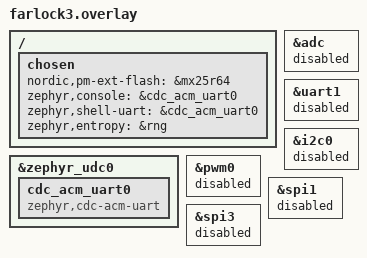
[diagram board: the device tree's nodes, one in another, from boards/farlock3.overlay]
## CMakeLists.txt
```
cmake_minimum_required(VERSION 3.20.0)

find_package(Zephyr HINTS $ENV{ZEPHYR_BASE})

project(app)

# Enable GNU STD support.
include(${ZEPHYR_CONNECTEDHOMEIP_MODULE_DIR}/config/nrfconnect/app/enable-gnu-std.cmake)

# NORDIC SDK APP START

# Include all source files that are located in the Matter common directory.
include(${ZEPHYR_NRF_MODULE_DIR}/samples/matter/common/cmake/source_common.cmake)

# Include Data Model utils
include(${ZEPHYR_NRF_MODULE_DIR}/samples/matter/common/cmake/data_model.cmake)

include(${ZEPHYR_NRF_MODULE_DIR}/samples/matter/common/cmake/zap_helpers.cmake)
ncs_get_zap_parent_dir(ZAP_PARENT_DIR)

target_include_directories(app PRIVATE
        src
        ${ZAP_PARENT_DIR}
)

target_sources(app PRIVATE
        #src/app_task.cpp
        #src/main.cpp
        src/main.c
        src/nfc.c
        src/usb.c
)

ncs_configure_data_model()
# NORDIC SDK APP END
```

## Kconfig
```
mainmenu "FARLock3 Application"

# Sample configuration used for Thread networking
if OPENTHREAD

choice OPENTHREAD_NORDIC_LIBRARY_CONFIGURATION
	default OPENTHREAD_NORDIC_LIBRARY_MTD
endchoice

choice OPENTHREAD_DEVICE_TYPE
	default OPENTHREAD_MTD
endchoice

endif # OPENTHREAD

source "${ZEPHYR_CONNECTEDHOMEIP_MODULE_DIR}/config/nrfconnect/chip-module/Kconfig.features"
source "${ZEPHYR_CONNECTEDHOMEIP_MODULE_DIR}/config/nrfconnect/chip-module/Kconfig.defaults"
source "${ZEPHYR_NRF_MODULE_DIR}/samples/matter/common/src/Kconfig"
source "Kconfig.zephyr"
```

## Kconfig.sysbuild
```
#
# Copyright (c) 2023 Nordic Semiconductor ASA
#
# SPDX-License-Identifier: LicenseRef-Nordic-5-Clause
#

config WIFI_NRF70
	default y if BOARD_NRF7002DK

#### Radio core selection
config NRF_DEFAULT_IPC_RADIO
	default y

# Enable IEEE802.15.4 serialization to network core
# This config automatically pulls in the `overlay-802154.conf` in the ipc_radio image
config NETCORE_IPC_RADIO_IEEE802154
	default y if SOC_SERIES_NRF53X && !WIFI_NRF70

# Enable Bluetooth serialization to network core
# This config automatically pulls in the `overlay-bt_hci_ipc.conf` in the ipc_radio image
config NETCORE_IPC_RADIO_BT_HCI_IPC
	default y if SOC_SERIES_NRF53X

#### Bootloader
choice BOOTLOADER
	default BOOTLOADER_MCUBOOT if !BOARD_NRF21540DK
endchoice

if BOOTLOADER_MCUBOOT

#### DFU multi-image support
config DFU_MULTI_IMAGE_PACKAGE_BUILD
	default y

config DFU_MULTI_IMAGE_PACKAGE_APP
	default y

config PM_EXTERNAL_FLASH_MCUBOOT_SECONDARY
	default y

#### DFU network core configuration
if SOC_SERIES_NRF53X

config MCUBOOT_UPDATEABLE_IMAGES
	default 2

choice MCUBOOT_MODE
	default MCUBOOT_MODE_OVERWRITE_ONLY
endchoice

choice BOOT_SIGNATURE_TYPE
	default BOOT_SIGNATURE_TYPE_RSA
endchoice

config SECURE_BOOT_NETCORE
	default y

config NETCORE_APP_UPDATE
	default y

config DFU_MULTI_IMAGE_PACKAGE_NET
	default y

endif # SOC_SERIES_NRF53X

if (BOARD_NRF54L15DK || BOARD_NRF54LM20PDK)

config PM_OVERRIDE_EXTERNAL_DRIVER_CHECK
	default y

endif # (BOARD_NRF54L15DK || BOARD_NRF54LM20PDK)

# Mcuboot padding size is modified to 0x1000 in pm_static file.
if SOC_NRF54L10

config PM_MCUBOOT_PAD
	default 0x1000

endif # SOC_NRF54L10

endif # BOOTLOADER_MCUBOOT

#### Enable generating factory data
config MATTER_FACTORY_DATA_GENERATE
	default y if !BOARD_NRF21540DK

source "share/sysbuild/Kconfig"
```

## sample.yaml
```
# This file is provided so that the application can be compiled using Twister,
# the Zephyr testing tool. In this file, multiple combinations can be specified,
# so that you can easily test all of them locally or in CI.
sample:
  description: NCS FAR Device
  name: example-application
common:
  build_only: true
  integration_platforms:
    - farlock
tests:
  app.default: {}
  app.debug:
    extra_overlay_confs:
      - debug.conf
```

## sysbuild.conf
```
SB_CONFIG_MATTER=y
```

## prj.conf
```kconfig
CONFIG_NCS_APPLICATION_BOOT_BANNER_STRING="FARLock3"

#Enable USB
CONFIG_USB_DEVICE_STACK=y
CONFIG_USB_DEVICE_PRODUCT="FARLock3"
CONFIG_USB_DEVICE_PID=0x0004
CONFIG_USB_DEVICE_INITIALIZE_AT_BOOT=n

#Configure NFC
CONFIG_NFC_T2T_NRFXLIB=y
CONFIG_NFC_NDEF=y
CONFIG_NFC_NDEF_MSG=y
CONFIG_NFC_NDEF_RECORD=y
CONFIG_NFC_NDEF_URI_REC=y
CONFIG_NFC_NDEF_LAUNCHAPP_MSG=y

#Enable Console
CONFIG_SERIAL=y
CONFIG_CONSOLE=y
CONFIG_UART_CONSOLE=y
CONFIG_UART_LINE_CTRL=y

# Enable CHIP
CONFIG_CHIP=y
CONFIG_CHIP_PROJECT_CONFIG="src/chip_project_config.h"

# Configure ZAP file name
CONFIG_NCS_SAMPLE_MATTER_ZAP_FILE_PATH="${APPLICATION_CONFIG_DIR}/src/default_zap/farlock3.zap"

# 32768 == 0x8000 (example Product ID added temporaly,
# but it must be changed with proper PID from the list:
# https://github.com/project-chip/connectedhomeip/blob/482e6fd03196a6de45465a90003947ef4b86e0b1/docs/examples/discussion/PID_allocation_for_example_apps.md)
CONFIG_CHIP_DEVICE_PRODUCT_ID=32768
CONFIG_STD_CPP17=y

# Enable Matter pairing automatically on application start.
CONFIG_CHIP_ENABLE_PAIRING_AUTOSTART=y

# Enable Matter extended announcement and increase duration to 1 hour.
CONFIG_CHIP_BLE_EXT_ADVERTISING=y
CONFIG_CHIP_BLE_ADVERTISING_DURATION=60

# Bluetooth Low Energy configuration
CONFIG_BT_DEVICE_NAME="FARLock3"

# Other settings
CONFIG_THREAD_NAME=y
CONFIG_MPU_STACK_GUARD=y
CONFIG_RESET_ON_FATAL_ERROR=n
CONFIG_CHIP_LIB_SHELL=y
CONFIG_NCS_SAMPLE_MATTER_TEST_SHELL=y

# Disable NFC commissioning
CONFIG_CHIP_NFC_COMMISSIONING=n

# Reduce application size
CONFIG_USE_SEGGER_RTT=n

# Enable Factory Data feature
CONFIG_CHIP_FACTORY_DATA=y
CONFIG_CHIP_FACTORY_DATA_BUILD=y
```

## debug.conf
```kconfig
# Copyright (c) 2021 Nordic Semiconductor ASA
# SPDX-License-Identifier: Apache-2.0
#
# This is a Kconfig fragment which can be used to enable debug-related options
# in the application. See the README for more details.

# compiler
CONFIG_DEBUG_OPTIMIZATIONS=y

# logging
CONFIG_LOG=y
CONFIG_APP_LOG_LEVEL_DBG=y

CONFIG_SHELL=y
CONFIG_PRINTK=y

CONFIG_STDOUT_CONSOLE=y
CONFIG_USB_DEVICE_STACK=y
CONFIG_USB_CDC_ACM=y
CONFIG_USB_DEVICE_MANUFACTURER="frazieje"
CONFIG_USB_DEVICE_PRODUCT="FARLock v2"
CONFIG_USB_DEVICE_PID=0x0001
CONFIG_USB_DRIVER_LOG_LEVEL_ERR=y
CONFIG_UART_INTERRUPT_DRIVEN=y
CONFIG_UART_LINE_CTRL=y
CONFIG_USB_DEVICE_INITIALIZE_AT_BOOT=y
```

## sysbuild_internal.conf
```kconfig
SB_CONFIG_MATTER=y
SB_CONFIG_PM_OVERRIDE_EXTERNAL_DRIVER_CHECK=n
SB_CONFIG_PM_EXTERNAL_FLASH_MCUBOOT_SECONDARY=n

# Enable the DFU image compression.
SB_CONFIG_MCUBOOT_MODE_OVERWRITE_ONLY=y
SB_CONFIG_MCUBOOT_COMPRESSED_IMAGE_SUPPORT=y
```

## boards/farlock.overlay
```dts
/ {
	chosen {
		nordic,pm-ext-flash = &mx25r64;
	};
};

/ {
	chosen {
		zephyr,entropy = &rng;
	};
};

/* Disable unused peripherals to reduce power consumption */
&adc {
	status = "disabled";
};
&uart1 {
	status = "disabled";
};
&i2c0 {
	status = "disabled";
};
&pwm0 {
	status = "disabled";
};
&spi1 {
	status = "disabled";
};
&spi3 {
	status = "disabled";
};
&usbd {
	status = "disabled";
};
```

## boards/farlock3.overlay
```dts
/ {
	chosen {
		nordic,pm-ext-flash = &mx25r64;
	};
};

/ {
	chosen {
		zephyr,console = &cdc_acm_uart0;
	};
};

/ {
	chosen {
		zephyr,shell-uart = &cdc_acm_uart0;
	};
};

/ {
	chosen {
		zephyr,entropy = &rng;
	};
};

&zephyr_udc0 {
	cdc_acm_uart0: cdc_acm_uart0 {
		compatible = "zephyr,cdc-acm-uart";
	};
};

/* Disable unused peripherals to reduce power consumption */
&adc {
	status = "disabled";
};
&uart1 {
	status = "disabled";
};
&i2c0 {
	status = "disabled";
};
&pwm0 {
	status = "disabled";
};
&spi1 {
	status = "disabled";
};
&spi3 {
	status = "disabled";
};
```

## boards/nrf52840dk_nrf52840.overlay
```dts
/* Copyright (c) 2021 Nordic Semiconductor ASA
 *
 * SPDX-License-Identifier: LicenseRef-Nordic-5-Clause
 */

/ {
	chosen {
		nordic,pm-ext-flash = &mx25r64;
	};
};

/ {
	chosen {
		zephyr,console = &cdc_acm_uart0;
	};
};

/ {
	chosen {
		zephyr,shell-uart = &cdc_acm_uart0;
	};
};

/ {
	/*
	* In some default configurations within the nRF Connect SDK,
	* e.g. on nRF52840, the chosen zephyr,entropy node is &cryptocell.
	* This devicetree overlay ensures that default is overridden wherever it
	* is set, as this application uses the RNG node for entropy exclusively.
	*/
	chosen {
		zephyr,entropy = &rng;
	};
};

&zephyr_udc0 {
	cdc_acm_uart0: cdc_acm_uart0 {
		compatible = "zephyr,cdc-acm-uart";
	};
};

/* Disable unused peripherals to reduce power consumption */
&adc {
	status = "disabled";
};
&uart1 {
	status = "disabled";
};
&i2c0 {
	status = "disabled";
};
&pwm0 {
	status = "disabled";
};
&spi1 {
	status = "disabled";
};
&spi3 {
	status = "disabled";
};
```

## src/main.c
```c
#include <zephyr/kernel.h>
#include "nfc.h"
#include "usb.h"

int main()
{
    printk("Started C application \n");

    start_usb();

    start_nfc();

    return 0;
}
```

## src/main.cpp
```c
#include <zephyr/kernel.h>

extern "C" {
#include "nfc.h"
#include "usb.h"
}

#define NFC_PATH DT_PATH(nfc)
#if DT_NODE_EXISTS(NFC_PATH)
#define NFC_TYPE_RO "nfc-ro"
#define NFC_TYPE_RW "nfc-rw"
/**
 * @brief Callback function for handling NFC events.
 */
static void nfc_callback(void *context,
                         nfc_t4t_event_t event,
                         const uint8_t *data,
                         size_t data_length,
                         uint32_t flags)
{
    ARG_UNUSED(context);
    ARG_UNUSED(data);
    ARG_UNUSED(flags);

    switch (event) {
        case NFC_T4T_EVENT_FIELD_ON:
            printk("NFC_T4T_EVENT_FIELD_ON\n");
            break;

        case NFC_T4T_EVENT_FIELD_OFF:
            printk("NFC_T4T_EVENT_FIELD_OFF\n");
            break;

        case NFC_T4T_EVENT_NDEF_READ:
            printk("NFC_T4T_EVENT_NDEF_READ\n");
            break;

        case NFC_T4T_EVENT_NDEF_UPDATED:
            if (data_length > 0) {
                printk("NFC_T4T_EVENT_NDEF_UPDATED\n");
            }
            break;

        default:
            break;
    }
}
#endif

int main()
{
    printk("Started C++ application \n");

    start_usb();


#if DT_NODE_EXISTS(NFC_PATH)
    char nfc_type[] = DT_PROP(NFC_PATH, compatible);
    int result;
    if (strcmp(NFC_TYPE_RO, nfc_type) == 0) {
        printk("NFC type is read only\n");
        result = start_nfc_ro(nfc_callback);
    } else if (strcmp(NFC_TYPE_RW, nfc_type) == 0) {
        printk("NFC type is read write\n");
        result = start_nfc_rw(nfc_callback);
    } else {
        printk("NFC type is unknown, ignoring.\n");
    }
    if (result != 0) {
        printk("Problem starting NFC\n");
        return 0;
    } else {
        printk("NFC tag emulation started!\n");
    }
#endif

    return 0;
}
```

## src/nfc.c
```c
#include "nfc.h"

int start_nfc() {
    return 0;
}
```

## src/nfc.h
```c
#ifndef NCSFARDEVICE_NFC_H
#define NCSFARDEVICE_NFC_H

/**
 * @brief Function for initializing and starting NFC services
 *
 * @return 0 when module has been set up properly,
 * error code otherwise.
 */
int start_nfc();

#endif //NCSFARDEVICE_NFC_H
```

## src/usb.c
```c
#include "usb.h"

#include <zephyr/usb/usb_device.h>
#include <zephyr/drivers/usb/usb_dc.h>
#include <zephyr/usb/usbd.h>
#include <zephyr/drivers/uart.h>

int start_usb() {
    const struct device *const dev = DEVICE_DT_GET(DT_CHOSEN(zephyr_console));
    uint32_t dtr = 0;

    if (usb_enable(NULL)) {
        return 0;
    }

    /* Poll if the DTR flag was set */
    while (!dtr) {
        uart_line_ctrl_get(dev, UART_LINE_CTRL_DTR, &dtr);
        /* Give CPU resources to low priority threads. */
        k_sleep(K_MSEC(100));
    }

    return 0;
}
```

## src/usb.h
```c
#ifndef NCSFARDEVICE_USB_H
#define NCSFARDEVICE_USB_H

int start_usb();

#endif
```
